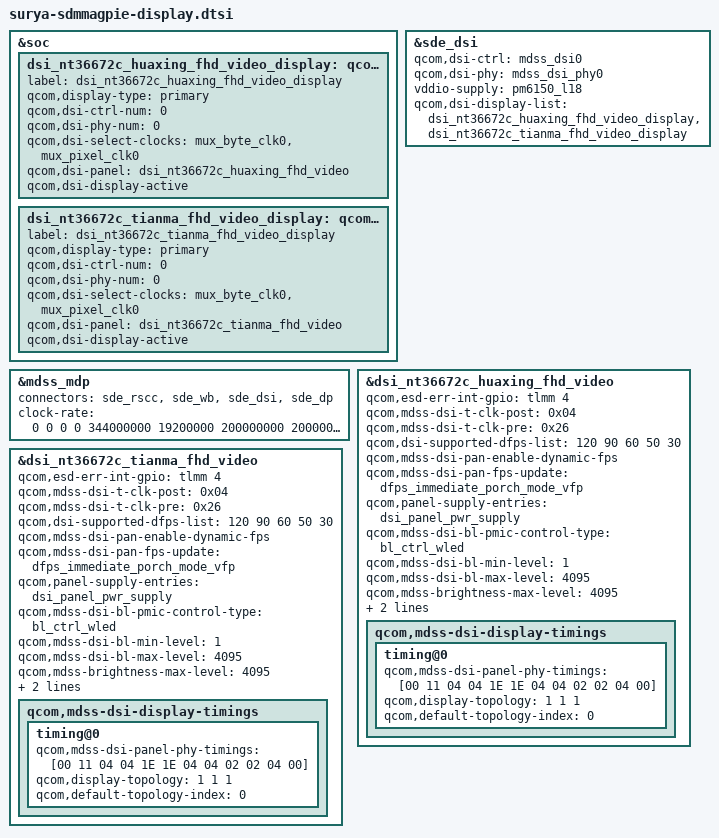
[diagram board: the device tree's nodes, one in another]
#include "display/dsi-panel-nt36672c-tianma-fhd-video.dtsi"
#include "display/dsi-panel-nt36672c-huaxing-fhd-video.dtsi"

&soc {
	dsi_nt36672c_huaxing_fhd_video_display: qcom,dsi-display@22 {
		label = "dsi_nt36672c_huaxing_fhd_video_display";
		qcom,display-type = "primary";
		qcom,dsi-ctrl-num = <0>;
		qcom,dsi-phy-num = <0>;
		qcom,dsi-select-clocks = "mux_byte_clk0", "mux_pixel_clk0";

		qcom,dsi-panel = <&dsi_nt36672c_huaxing_fhd_video>;
		qcom,dsi-display-active;
	};

	dsi_nt36672c_tianma_fhd_video_display: qcom,dsi-display@23 {
		label = "dsi_nt36672c_tianma_fhd_video_display";
		qcom,display-type = "primary";
		qcom,dsi-ctrl-num = <0>;
		qcom,dsi-phy-num = <0>;
		qcom,dsi-select-clocks = "mux_byte_clk0", "mux_pixel_clk0";

		qcom,dsi-panel = <&dsi_nt36672c_tianma_fhd_video>;
		qcom,dsi-display-active;
	};
};

&sde_dsi {
	qcom,dsi-ctrl = <&mdss_dsi0>;
	qcom,dsi-phy = <&mdss_dsi_phy0>;

	vddio-supply = <&pm6150_l18>;
	/delete-property/ vdda-3p3-supply;

	qcom,dsi-display-list =
			<&dsi_nt36672c_huaxing_fhd_video_display
			&dsi_nt36672c_tianma_fhd_video_display>;
};

&mdss_mdp {
	connectors = <&sde_rscc &sde_wb &sde_dsi &sde_dp>;
	clock-rate = <0 0 0 0 344000000 19200000 200000000
					200000000>;
};

&dsi_nt36672c_huaxing_fhd_video {
	qcom,esd-err-int-gpio = <&tlmm 4 0>;
	qcom,mdss-dsi-t-clk-post = <0x04>;
	qcom,mdss-dsi-t-clk-pre = <0x26>;
	qcom,dsi-supported-dfps-list = <120 90 60 50 30>;
	qcom,mdss-dsi-pan-enable-dynamic-fps;
	qcom,mdss-dsi-pan-fps-update = "dfps_immediate_porch_mode_vfp";
	qcom,panel-supply-entries = <&dsi_panel_pwr_supply>;
	qcom,mdss-dsi-bl-pmic-control-type = "bl_ctrl_wled";
	qcom,mdss-dsi-bl-min-level = <1>;
	qcom,mdss-dsi-bl-max-level = <4095>;
	qcom,mdss-brightness-max-level = <4095>;
	qcom,platform-te-gpio = <&tlmm 10 0>;
	qcom,platform-reset-gpio = <&pm6150l_gpios 9 0>;
	qcom,mdss-dsi-display-timings {
		timing@0{
			qcom,mdss-dsi-panel-phy-timings =[00 11 04 04 1E 1E 04
				 04 02 02 04 00];
			qcom,display-topology = <1 1 1>;
			qcom,default-topology-index = <0>;
		};
	};
};

&dsi_nt36672c_tianma_fhd_video {
	qcom,esd-err-int-gpio = <&tlmm 4 0>;
	qcom,mdss-dsi-t-clk-post = <0x04>;
	qcom,mdss-dsi-t-clk-pre = <0x26>;
	qcom,dsi-supported-dfps-list = <120 90 60 50 30>;
	qcom,mdss-dsi-pan-enable-dynamic-fps;
	qcom,mdss-dsi-pan-fps-update = "dfps_immediate_porch_mode_vfp";
	qcom,panel-supply-entries = <&dsi_panel_pwr_supply>;
	qcom,mdss-dsi-bl-pmic-control-type = "bl_ctrl_wled";
	qcom,mdss-dsi-bl-min-level = <1>;
	qcom,mdss-dsi-bl-max-level = <4095>;
	qcom,mdss-brightness-max-level = <4095>;
	qcom,platform-te-gpio = <&tlmm 10 0>;
	qcom,platform-reset-gpio = <&pm6150l_gpios 9 0>;
	qcom,mdss-dsi-display-timings {
		timing@0{
			qcom,mdss-dsi-panel-phy-timings =[00 11 04 04 1E 1E 04
				 04 02 02 04 00];
			qcom,display-topology = <1 1 1>;
			qcom,default-topology-index = <0>;
		};
	};
};
